# HC32F448MCTI register map
File version: 1.0
CPU: CM4 r0p1, little endian, MPU, FPU, 4 interrupt priority bits
Registers are 32-bit, read-write, reset 0x0 unless marked. A register's access mark holds for its fields unless they carry their own. Offsets are from the block's base; [hi:lo] are bit positions; {n}, {i} and the like mark numbered series; 'fields as' and 'values as' point back to an identical list.

## CRC
Base 0x40008C00
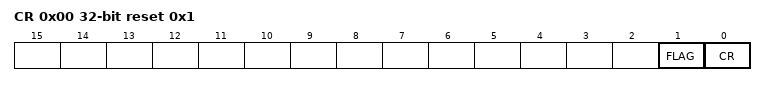
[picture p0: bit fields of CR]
0x00 CR reset 0x1
  [1] FLAG ro, [0] CR
0x04 RESLT
{0x80+4i} DAT{i} wo (i=0..31)

## CTC
Base 0x40049C00
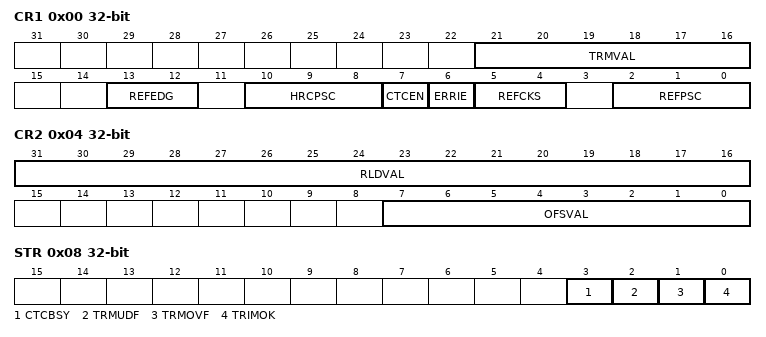
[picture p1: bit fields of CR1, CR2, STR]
0x00 CR1
  [21:16] TRMVAL, [13:12] REFEDG, [10:8] HRCPSC, [7] CTCEN, [6] ERRIE, [5:4] REFCKS, [2:0] REFPSC
0x04 CR2
  [31:16] RLDVAL, [7:0] OFSVAL
0x08 STR ro
  [3] CTCBSY, [2] TRMUDF, [1] TRMOVF, [0] TRIMOK
0x0C CNT 16-bit ro

## DAC
Base 0x40041000
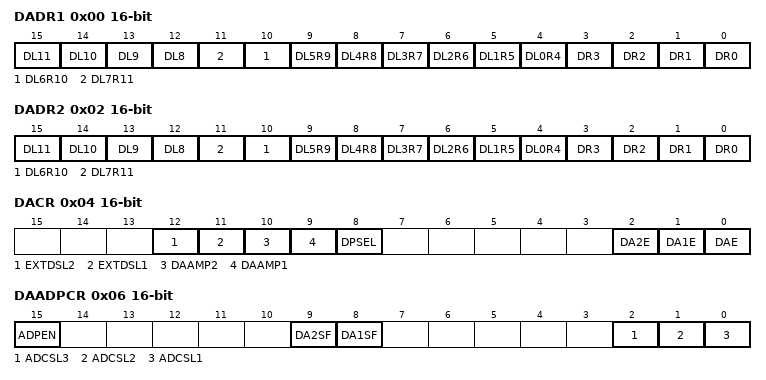
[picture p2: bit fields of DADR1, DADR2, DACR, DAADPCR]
0x00 DADR1 16-bit
  [n+4] DL{n} (n=8..11), [n+4] DL{n}R{n+4} (n=0..7), [n] DR{n} (n=0..3)
0x02 DADR2 16-bit
  fields as DADR1
0x04 DACR 16-bit
  [12] EXTDSL2, [11] EXTDSL1, [10] DAAMP2, [9] DAAMP1, [8] DPSEL, [2] DA2E, [1] DA1E, [0] DAE
0x06 DAADPCR 16-bit
  [15] ADPEN, [9] DA2SF ro, [8] DA1SF ro, [2] ADCSL3, [1] ADCSL2, [0] ADCSL1
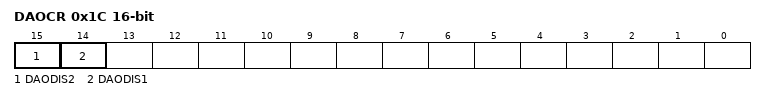
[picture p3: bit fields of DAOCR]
0x1C DAOCR 16-bit
  [15] DAODIS2, [14] DAODIS1

## DBGC
Base 0xE0042000
{0x0+4i} AUTHID{i} (i=0..2)
0x0C CHIPID ro reset 0x58480448
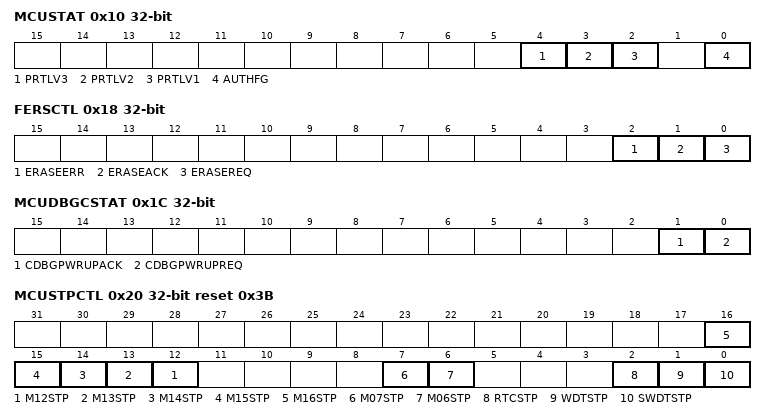
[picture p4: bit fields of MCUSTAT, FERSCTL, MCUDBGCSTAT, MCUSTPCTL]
0x10 MCUSTAT
  [4] PRTLV3, [3] PRTLV2, [2] PRTLV1, [0] AUTHFG
0x18 FERSCTL
  [2] ERASEERR, [1] ERASEACK, [0] ERASEREQ
0x1C MCUDBGCSTAT
  [1] CDBGPWRUPACK, [0] CDBGPWRUPREQ
0x20 MCUSTPCTL reset 0x3B
  [n] M{n}STP (n=12..16), [7] M07STP, [6] M06STP, [2] RTCSTP, [1] WDTSTP, [0] SWDTSTP
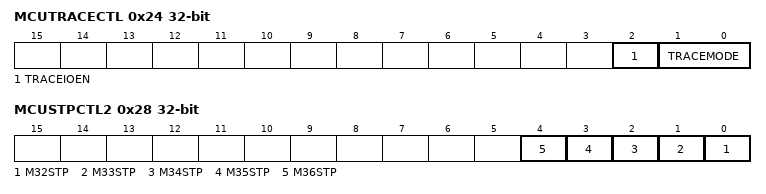
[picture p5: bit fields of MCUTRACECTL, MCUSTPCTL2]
0x24 MCUTRACECTL
  [2] TRACEIOEN, [1:0] TRACEMODE
0x28 MCUSTPCTL2
  [n-32] M{n}STP (n=32..36)

## DCU1 — desc DCU
Base 0x40056000
Same registers: DCU2 0x40056400, DCU3 0x40056800, DCU4 0x40056C00
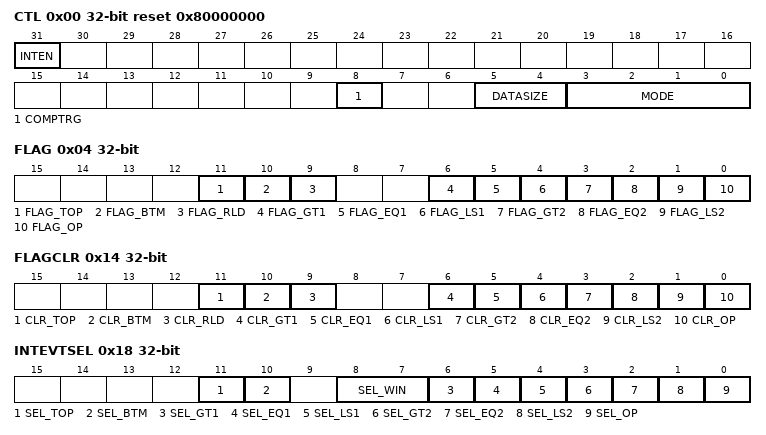
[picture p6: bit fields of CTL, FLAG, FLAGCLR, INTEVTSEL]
0x00 CTL reset 0x80000000
  [31] INTEN, [8] COMPTRG, [5:4] DATASIZE, [3:0] MODE
0x04 FLAG ro
  [11] FLAG_TOP, [10] FLAG_BTM, [9] FLAG_RLD, [6] FLAG_GT1, [5] FLAG_EQ1, [4] FLAG_LS1, [3] FLAG_GT2, [2] FLAG_EQ2, [1] FLAG_LS2, [0] FLAG_OP
{0x8+4i} DATA{i} (i=0..2)
0x14 FLAGCLR wo
  [11] CLR_TOP, [10] CLR_BTM, [9] CLR_RLD, [6] CLR_GT1, [5] CLR_EQ1, [4] CLR_LS1, [3] CLR_GT2, [2] CLR_EQ2, [1] CLR_LS2, [0] CLR_OP
0x18 INTEVTSEL
  [11] SEL_TOP, [10] SEL_BTM, [8:7] SEL_WIN, [6] SEL_GT1, [5] SEL_EQ1, [4] SEL_LS1, [3] SEL_GT2, [2] SEL_EQ2, [1] SEL_LS2, [0] SEL_OP

## DMA1 — desc DMA
Base 0x40053000
Same registers: DMA2 0x40053400
0x00 EN
  [0] EN
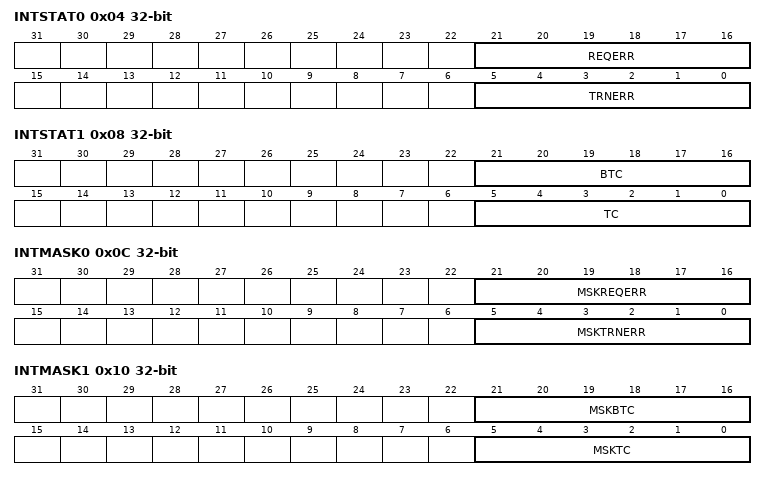
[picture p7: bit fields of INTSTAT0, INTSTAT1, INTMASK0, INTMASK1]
0x04 INTSTAT0 ro
  [21:16] REQERR, [5:0] TRNERR
0x08 INTSTAT1 ro
  [21:16] BTC, [5:0] TC
0x0C INTMASK0
  [21:16] MSKREQERR, [5:0] MSKTRNERR
0x10 INTMASK1
  [21:16] MSKBTC, [5:0] MSKTC
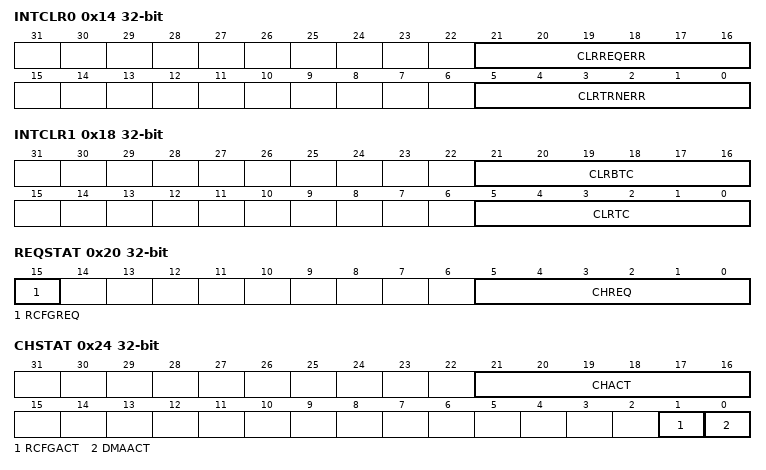
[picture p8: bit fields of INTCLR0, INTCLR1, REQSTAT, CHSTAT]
0x14 INTCLR0 wo
  [21:16] CLRREQERR, [5:0] CLRTRNERR
0x18 INTCLR1 wo
  [21:16] CLRBTC, [5:0] CLRTC
0x1C CHEN
  [5:0] CHEN
0x20 REQSTAT ro
  [15] RCFGREQ, [5:0] CHREQ
0x24 CHSTAT ro
  [21:16] CHACT, [1] RCFGACT, [0] DMAACT
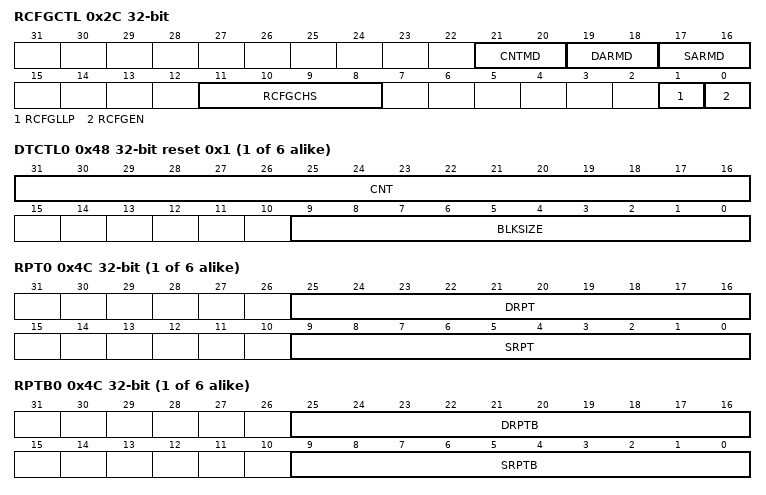
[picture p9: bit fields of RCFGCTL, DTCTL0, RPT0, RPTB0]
0x2C RCFGCTL
  [21:20] CNTMD, [19:18] DARMD, [17:16] SARMD, [11:8] RCFGCHS, [1] RCFGLLP, [0] RCFGEN
0x34 CHENCLR wo
  [5:0] CHENCLR
{0x40+0x40*i} SAR{i} (i=0..5)
{0x44+0x40*i} DAR{i} (i=0..5)
{0x48+0x40*i} DTCTL{i} reset 0x1 (i=0..5)
  [31:16] CNT, [9:0] BLKSIZE
{0x4C+0x40*i} RPT{i} (i=0..5)
  [25:16] DRPT, [9:0] SRPT
{0x4C+0x40*i} RPTB{i} (alternate view of RPT{i}) (i=0..5)
  [25:16] DRPTB, [9:0] SRPTB
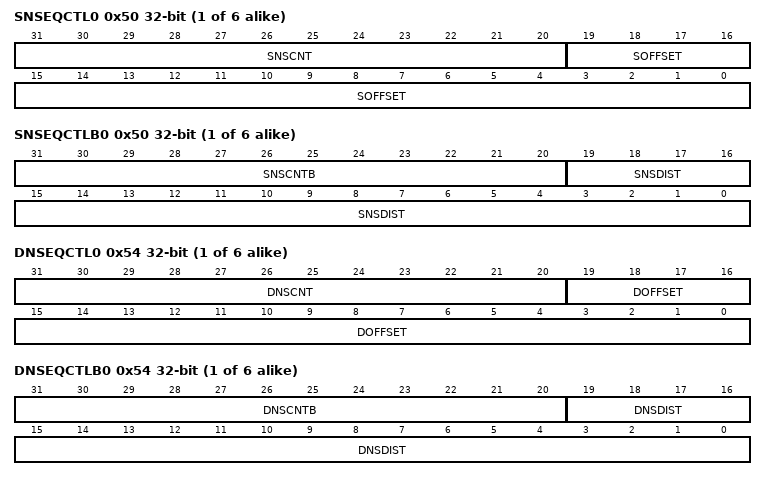
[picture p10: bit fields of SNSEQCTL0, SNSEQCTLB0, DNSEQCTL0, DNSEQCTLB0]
{0x50+0x40*i} SNSEQCTL{i} (i=0..5)
  [31:20] SNSCNT, [19:0] SOFFSET
{0x50+0x40*i} SNSEQCTLB{i} (alternate view of SNSEQCTL{i}) (i=0..5)
  [31:20] SNSCNTB, [19:0] SNSDIST
{0x54+0x40*i} DNSEQCTL{i} (i=0..5)
  [31:20] DNSCNT, [19:0] DOFFSET
{0x54+0x40*i} DNSEQCTLB{i} (alternate view of DNSEQCTL{i}) (i=0..5)
  [31:20] DNSCNTB, [19:0] DNSDIST
{0x58+0x40*i} LLP{i} (i=0..5)
  [31:2] LLP
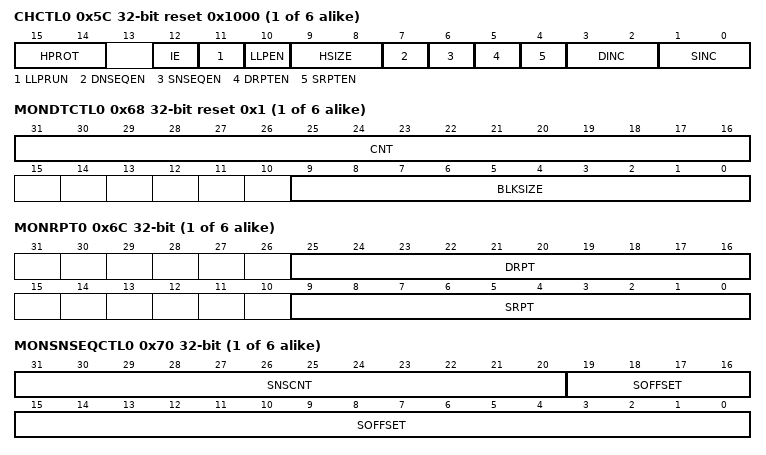
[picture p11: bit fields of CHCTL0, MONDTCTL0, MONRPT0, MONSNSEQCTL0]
{0x5C+0x40*i} CHCTL{i} reset 0x1000 (i=0..5)
  [15:14] HPROT, [12] IE, [11] LLPRUN, [10] LLPEN, [9:8] HSIZE, [7] DNSEQEN, [6] SNSEQEN, [5] DRPTEN, [4] SRPTEN, [3:2] DINC, [1:0] SINC
{0x60+0x40*i} MONSAR{i} ro (i=0..5)
{0x64+0x40*i} MONDAR{i} ro (i=0..5)
{0x68+0x40*i} MONDTCTL{i} ro reset 0x1 (i=0..5)
  [31:16] CNT, [9:0] BLKSIZE
{0x6C+0x40*i} MONRPT{i} ro (i=0..5)
  [25:16] DRPT, [9:0] SRPT
{0x70+0x40*i} MONSNSEQCTL{i} ro (i=0..5)
  [31:20] SNSCNT, [19:0] SOFFSET
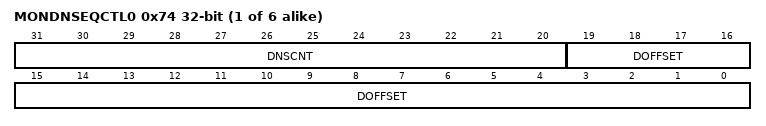
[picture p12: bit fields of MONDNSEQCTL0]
{0x74+0x40*i} MONDNSEQCTL{i} ro (i=0..5)
  [31:20] DNSCNT, [19:0] DOFFSET
